# MAX32550 register map
Vendor: Maxim Integrated; File version: 1.0
Registers are 32-bit, read-write, reset 0x0 unless marked. A register's access mark holds for its fields unless they carry their own. Offsets are from the block's base; [hi:lo] are bit positions; {n}, {i} and the like mark numbered series; 'fields as' and 'values as' point back to an identical list.

## DMAController — Fully programmable, chaining capable DMA channels
Base 0x40028000; register names take the prefix DMA
0x00 _CN 4-bit — DMA Control Register
  [all] fields
    0=disable; 1=enable
  [n] CH{n}_IEN (n=0..3) — Channel {n} Interrupt Enable
0x04 _INT 4-bit ro — DMA Interrupt Register
  [all] fields
    0=inactive (No interrupt is pending); 1=pending (An interrupt is pending)
  [n] CH{n}_IPEND (n=0..3) — Channel Interrupt. To clear an interrupt, all active interrupt bits of the DMA_ST must be cleared. The interrupt bits are set only if their corresponding interrupt enable bits are set in DMA_CN.
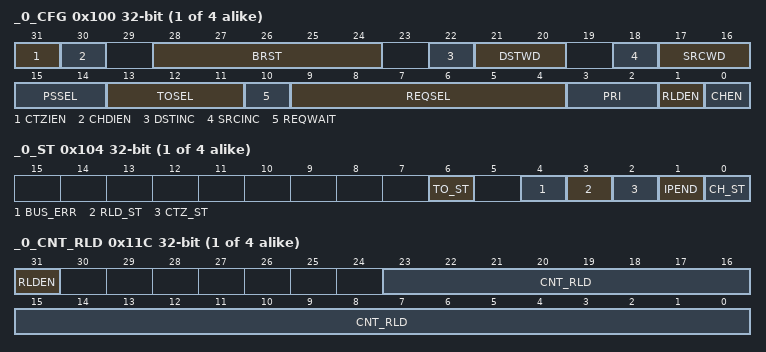
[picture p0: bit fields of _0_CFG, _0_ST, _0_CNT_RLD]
{0x100+0x20*i} _{i}_CFG (i=0..3) — DMA Channel Configuration Register
  [31] CTZIEN — Count-to-zero Interrupts Enable. When enabled, the IPEND will be set to 1 whenever a count-to-zero event occurs.
    0=disable; 1=enable
  [30] CHDIEN — Channel Disable Interrupt Enable. When enabled, the IPEND will be set to 1 whenever CH_ST changes from 1 to 0.
    0=disable; 1=enable
  [28:24] BRST — Burst Size. The number of bytes to be transferred into and out of the DMA FIFO in a single burst. Burst size equals 1 + value stored in this field.
  [22] DSTINC — Destination Increment Enable. This bit enables DMA_DST increment upon every AHB transaction. This bit is forced to 0 for DMA transmit to peripherals.
    0=disable; 1=enable
  [21:20] DSTWD — Destination Width. Indicates the width of the each AHB transactions to the destination peripheral or memory. (The actual width may be less than this if there are insufficient bytes in the DMA FIFO for the full width).
    0=byte; 1=halfWord; 2=word
  [18] SRCINC — Source Increment Enable. This bit enables DMA_SRC increment upon every AHB transaction. This bit is forced to 0 for DMA receive from peripherals.
    0=disable; 1=enable
  [17:16] SRCWD — Source Width. In most cases, this will be the data width of each AHB transactions. However, the width will be reduced in the cases where DMA_CNT indicates a smaller value.
    0=byte; 1=halfWord; 2=word
  [15:14] PSSEL — Pre-Scale Select. Selects the Pre-Scale divider for timer clock input.
    0=Disable timer; 1=div256 (hclk / 256); 2=div64k (hclk / 64k); 3=div16M (hclk / 16M)
  [13:11] TOSEL — Time-Out Select. Selects the number of prescale clocks seen by the channel timer before a time-out conditions is generated for this channel. Important note: since the prescaler runs independent of the individual channel timers, the actual number of Pre-Scale clock edges seen has a margin of error equal to a single Pre-Scale clock.
    0=to4 (Timeout of 3 to 4 prescale clocks); 1=to8 (Timeout of 7 to 8 prescale clocks); 2=to16 (Timeout of 15 to 16 prescale clocks); 3=to32 (Timeout of 31 to 32 prescale clocks); 4=to64 (Timeout of 63 to 64 prescale clocks); 5=to128 (Timeout of 127 to 128 prescale clocks); 6=to256 (Timeout of 255 to 256 prescale clocks); 7=to512 (Timeout of 511 to 512 prescale clocks)
  [10] REQWAIT — Request Wait Enable. When enabled, delay timer start until DMA request transitions from active to inactive.
    0=disable; 1=enable
  [9:4] REQSEL — Request Select. Select DMA request line for this channel. If memory-to-memory is selected, the channel operates as if the request is always active.
    0=memToMem; 1=spi0Rx; 2=spi1Rx; 3=spi2Rx; 4=uart0Rx; 5=uart1Rx; 7=i2cRx; 11=msrT1Rx; 12=msrT2Rx; 13=msrT3Rx; 33=spi0Tx; 34=spi1Tx; 35=spi2Tx; 36=uart0Tx; 37=uart1Tx; 39=i2cTx
  [3:2] PRI — DMA Priority
    0=Highest Priority; 1=medHigh; 2=medLow; 3=low (Lowest Priority)
  [1] RLDEN — Reload Enable. Setting this bit to 1 enables DMA_SRC, DMA_DST and DMA_CNT to be reloaded with their corresponding reload registers upon count-to-zero. This bit is also writeable in the Count Reload Register. Refer to the description on Buffer Chaining for use of this bit. If buffer chaining is not used this bit must be written with a 0. This bit should be set after the reload registers have been programmed.
    0=disable; 1=enable
  [0] CHEN — Channel Enable. This bit is automatically cleared when DMA_ST.CH_ST changes from 1 to 0.
    0=disable; 1=enable
{0x104+0x20*i} _{i}_ST (i=0..3) — DMA Channel Status Register
  [6] TO_ST write-1-clears — Time-Out Status
    on read: 0=noEvent (The event has not occurred); 1=occurred (The event has occurred) | on write: 1=clear
  [4] BUS_ERR write-1-clears — Bus Error. Indicates that an AHB abort was received and the channel has been disabled.
    values as TO_ST
  [3] RLD_ST write-1-clears — Reload Status
    values as TO_ST
  [2] CTZ_ST write-1-clears — Count-to-Zero (CTZ) Status
    values as TO_ST
  [1] IPEND ro — Channel Interrupt
    values as the fields of _INT
  [0] CH_ST ro — Channel Status. This bit is used to indicate to the programmer when it is safe to change the configuration, address, and count registers for the channel. Whenever this bit is cleared by hardware, the DMA_CFG.CHEN bit is also cleared (if not cleared already).
    0=disable; 1=enable
{0x108+0x20*i} _{i}_SRC (i=0..3) — Source Device Address. If SRCINC=1, the counter bits are incremented by 1,2, or 4, depending on the data width of each AHB cycle. For peripheral transfers, some or all of the actual address bits are fixed. If SRCINC=0, this register remains constant. In the case where a count-to-zero condition occurs while RLDEN=1, the register is reloaded with the contents of DMA_SRC_RLD.
{0x10C+0x20*i} _{i}_DST (i=0..3) — Destination Device Address. For peripheral transfers, some or all of the actual address bits are fixed. If DSTINC=1, this register is incremented on every AHB write out of the DMA FIFO. They are incremented by 1, 2, or 4, depending on the data width of each AHB cycle. In the case where a count-to-zero condition occurs while RLDEN=1, the register is reloaded with DMA_DST_RLD.
{0x110+0x20*i} _{i}_CNT (i=0..3) 24-bit — DMA Counter. The user loads this register with the number of bytes to transfer. This counter decreases on every AHB cycle into the DMA FIFO. The decrement will be 1, 2, or 4 depending on the data width of each AHB cycle. When the counter reaches 0, a count-to-zero condition is triggered.
{0x114+0x20*i} _{i}_SRC_RLD (i=0..3) 31-bit — Source Address Reload Value. The value of this register is loaded into DMA0_SRC upon a count-to-zero condition.
{0x118+0x20*i} _{i}_DST_RLD (i=0..3) 31-bit — Destination Address Reload Value. The value of this register is loaded into DMA0_DST upon a count-to-zero condition.
{0x11C+0x20*i} _{i}_CNT_RLD (i=0..3) — DMA Channel Count Reload Register
  [31] RLDEN — Reload Enable. This bit should be set after the address reload registers have been programmed. This bit is automatically cleared to 0 when reload occurs.
    0=disable; 1=enable
  [23:0] CNT_RLD — Count Reload Value. The value of this register is loaded into DMA0_CNT upon a count-to-zero condition.
